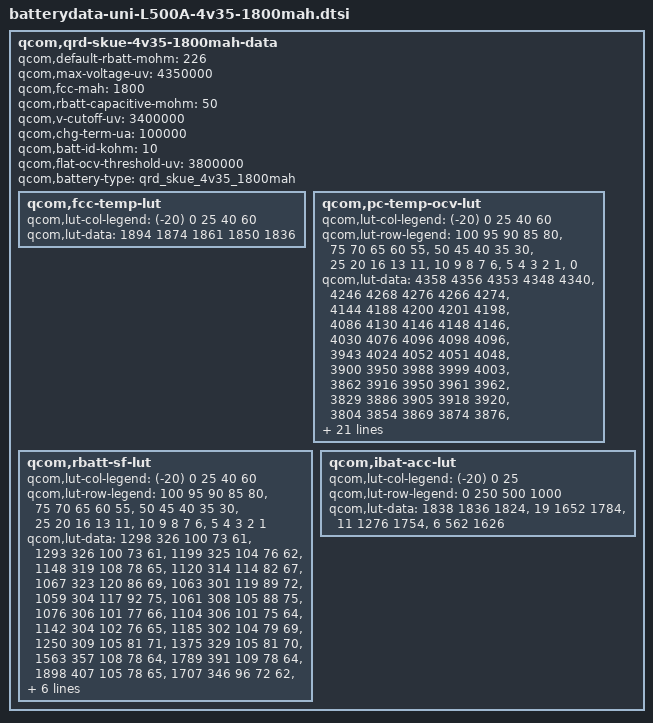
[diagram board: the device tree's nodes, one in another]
/**********uniscope-driver-modify-file-on-qualcomm-platform*****************/
/* Copyright (c) 2014, The Linux Foundation. All rights reserved.
 *
 * This program is free software; you can redistribute it and/or modify
 * it under the terms of the GNU General Public License version 2 and
 * only version 2 as published by the Free Software Foundation.
 *
 * This program is distributed in the hope that it will be useful,
 * but WITHOUT ANY WARRANTY; without even the implied warranty of
 * MERCHANTABILITY or FITNESS FOR A PARTICULAR PURPOSE.  See the
 * GNU General Public License for more details.
 */


qcom,qrd-skue-4v35-1800mah-data {
	qcom,default-rbatt-mohm = <226>;
	qcom,max-voltage-uv = <4350000>;
	qcom,fcc-mah = <1800>;
	qcom,rbatt-capacitive-mohm = <50>;
	qcom,v-cutoff-uv = <3400000>;
	qcom,chg-term-ua = <100000>;
	qcom,batt-id-kohm = <10>;
	qcom,flat-ocv-threshold-uv = <3800000>;
	qcom,battery-type = "qrd_skue_4v35_1800mah";

	qcom,fcc-temp-lut {
		qcom,lut-col-legend = <(-20) 0 25 40 60>;
		qcom,lut-data = <1894 1874 1861 1850 1836>;
	};

	qcom,pc-temp-ocv-lut {
		qcom,lut-col-legend = <(-20) 0 25 40 60>;
		qcom,lut-row-legend = <100 95 90 85 80>,
				<75 70 65 60 55>,
				<50 45 40 35 30>,
				<25 20 16 13 11>,
				<10 9 8 7 6>,
				<5 4 3 2 1>,
				<0>;
		qcom,lut-data = 
				<4358 4356 4353 4348 4340>,
				<4246 4268 4276 4266 4274>,
				<4144 4188 4200 4201 4198>,
				<4086 4130 4146 4148 4146>,
				<4030 4076 4096 4098 4096>,
				<3943 4024 4052 4051 4048>,
				<3900 3950 3988 3999 4003>,
				<3862 3916 3950 3961 3962>,
				<3829 3886 3905 3918 3920>,
				<3804 3854 3869 3874 3876>,
				<3784 3824 3840 3843 3844>,
				<3767 3795 3816 3819 3820>,
				<3750 3770 3798 3800 3800>,
				<3732 3753 3780 3782 3783>,
				<3713 3741 3766 3766 3763>,
				<3692 3731 3752 3749 3738>,
				<3666 3721 3734 3730 3716>,
				<3640 3713 3712 3707 3694>,
				<3618 3704 3694 3685 3674>,
				<3598 3696 3689 3681 3670>,
				<3586 3690 3688 3680 3669>,
				<3573 3684 3686 3679 3668>,
				<3557 3675 3684 3678 3666>,
				<3541 3664 3681 3675 3663>,
				<3519 3647 3672 3667 3652>,
				<3494 3624 3646 3636 3621>,
				<3461 3588 3601 3589 3575>,
				<3417 3536 3538 3526 3514>,
				<3350 3456 3452 3442 3434>,
				<3231 3320 3324 3307 3308>,
				<3000 3000 3016 3000 3000>;
};

	qcom,rbatt-sf-lut {
		qcom,lut-col-legend = <(-20) 0 25 40 60>;
		qcom,lut-row-legend = <100 95 90 85 80>,
				<75 70 65 60 55>,
				<50 45 40 35 30>,
				<25 20 16 13 11>,
				<10 9 8 7 6>,
				<5 4 3 2 1>;
		qcom,lut-data = 
				<1298 326 100 73 61>,
				<1293 326 100 73 61>,
				<1199 325 104 76 62>,
				<1148 319 108 78 65>,
				<1120 314 114 82 67>,
				<1067 323 120 86 69>,
				<1063 301 119 89 72>,
				<1059 304 117 92 75>,
				<1061 308 105 88 75>,
				<1076 306 101 77 66>,
				<1104 306 101 75 64>,
				<1142 304 102 76 65>,
				<1185 302 104 79 69>,
				<1250 309 105 81 71>,
				<1375 329 105 81 70>,
				<1563 357 108 78 64>,
				<1789 391 109 78 64>,
				<1898 407 105 78 65>,
				<1707 346 96 72 62>,
				<1964 356 97 72 62>,
				<2156 363 100 74 64>,
				<2371 371 103 77 66>,
				<2598 380 108 81 68>,
				<2918 391 113 84 69>,
				<3354 405 117 85 69>,
				<3929 425 112 80 65>,
				<4766 451 110 79 66>,
				<6174 495 114 82 69>,
				<9096 574 123 91 76>,
				<18193 1148 162 165 92>;
	};

	qcom,ibat-acc-lut {
		qcom,lut-col-legend = <(-20) 0 25>;
		qcom,lut-row-legend = <0 250 500 1000>;
		qcom,lut-data = <1838 1836 1824>,
				<19  1652 1784>,
				<11  1276 1754>,
				<6   562 1626>;
	};
};
